VERSION ""

NS_ :

BS_:

BU_:

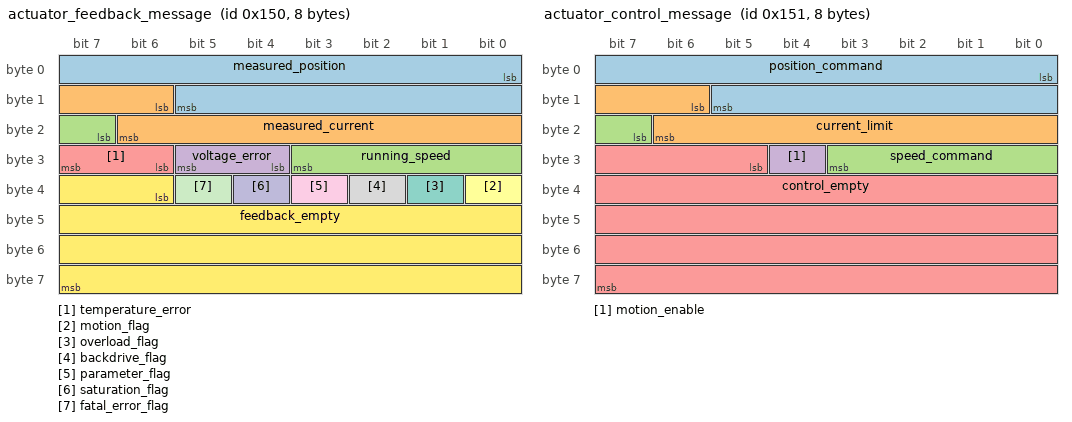
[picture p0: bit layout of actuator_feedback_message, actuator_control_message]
BO_ 336 actuator_feedback_message: 8 Vector__XXX
 SG_ measured_position : 0|14@1+ (0.1,0) [0|100] "mm" Vector__XXX
 SG_ measured_current : 14|9@1+ (0.1,0) [0|20] "A" Vector__XXX
 SG_ running_speed : 23|5@1+ (5,0) [0|100] "%" Vector__XXX
 SG_ voltage_error : 28|2@1+ (1,0) [0|2] "" Vector__XXX
 SG_ temperature_error : 30|2@1+ (1,0) [0|2] "" Vector__XXX
 SG_ motion_flag : 32|1@1+ (1,0) [0|1] "" Vector__XXX
 SG_ overload_flag : 33|1@1+ (1,0) [0|1] "" Vector__XXX
 SG_ backdrive_flag : 34|1@1+ (1,0) [0|1] "" Vector__XXX
 SG_ parameter_flag : 35|1@1+ (1,0) [0|1] "" Vector__XXX
 SG_ saturation_flag : 36|1@1+ (1,0) [0|1] "" Vector__XXX
 SG_ fatal_error_flag : 37|1@1+ (1,0) [0|1] "" Vector__XXX
 SG_ feedback_empty : 38|26@1+ (1,0) [0|255] "" Vector__XXX

BO_ 337 actuator_control_message: 8 Vector__XXX
 SG_ position_command : 0|14@1+ (0.1,0) [0|100] "mm" Vector__XXX
 SG_ current_limit : 14|9@1+ (0.1,0) [0|4] "A" Vector__XXX
 SG_ speed_command : 23|5@1+ (5,0) [20|100] "%" Vector__XXX
 SG_ motion_enable : 28|1@1+ (1,0) [0|1] "" Vector__XXX
 SG_ control_empty : 29|35@1+ (1,0) [0|0] "" Vector__XXX

CM_ BO_ 336 "actuator feedback message";
BA_DEF_  "BusType" STRING ;
BA_DEF_DEF_  "BusType" "CAN";
VAL_ 336 voltage_error 0 "normal_operation" 1 "undervoltage_flag" 2 "overvoltage_flag" ;
VAL_ 336 temperature_error 0 "normal_operation" 1 "undertemperature_flag" 2 "overtemperature_flag" ;
VAL_ 336 motion_flag 0 "stop" 1 "run" ;
VAL_ 336 overload_flag 0 "normal_operation" 1 "overload_condition" ;
VAL_ 336 backdrive_flag 0 "normal_operation" 1 "uncommanded_movement" ;
VAL_ 336 parameter_flag 0 "normal_operation" 1 "outside_allowed_parameter" ;
VAL_ 336 saturation_flag 0 "normal_operation" 1 "10%_capability" ;
VAL_ 336 fatal_error_flag 0 "normal_operation" 1 "failure" ;
VAL_ 337 motion_enable 1 "ON" 0 "OFF" ;
